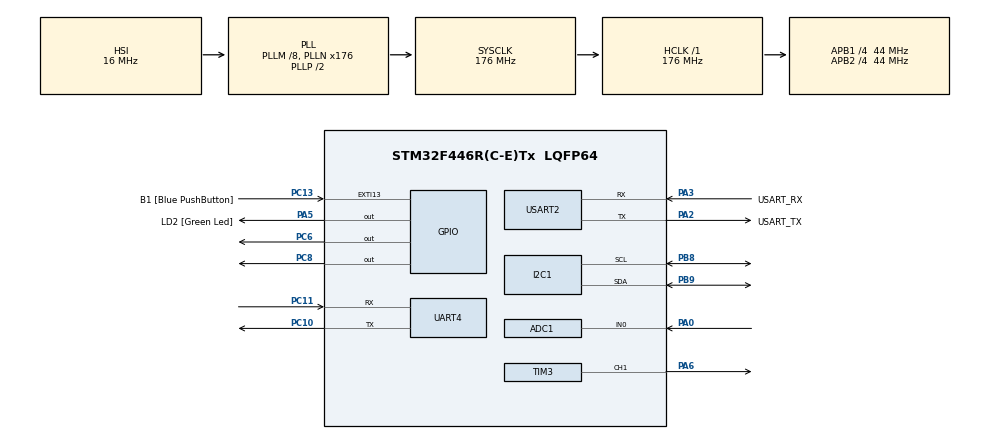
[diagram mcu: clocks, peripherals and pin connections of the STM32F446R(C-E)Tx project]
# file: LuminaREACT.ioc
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ADC1.Channel-0\#ChannelRegularConversion=ADC_CHANNEL_0
ADC1.ClockPrescaler=ADC_CLOCK_SYNC_PCLK_DIV4
ADC1.ContinuousConvMode=ENABLE
ADC1.DMAContinuousRequests=ENABLE
ADC1.EOCSelection=ADC_EOC_SEQ_CONV
ADC1.NbrOfConversion=1
ADC1.NbrOfConversionFlag=1
ADC1.Rank-0\#ChannelRegularConversion=1
ADC1.SamplingTime-0\#ChannelRegularConversion=ADC_SAMPLETIME_480CYCLES
ADC1.master=1
Dma.ADC1.0.Direction=DMA_PERIPH_TO_MEMORY
Dma.ADC1.0.FIFOMode=DMA_FIFOMODE_DISABLE
Dma.ADC1.0.Instance=DMA2_Stream0
Dma.ADC1.0.MemDataAlignment=DMA_MDATAALIGN_HALFWORD
Dma.ADC1.0.MemInc=DMA_MINC_ENABLE
Dma.ADC1.0.Mode=DMA_NORMAL
Dma.ADC1.0.PeriphDataAlignment=DMA_PDATAALIGN_HALFWORD
Dma.ADC1.0.PeriphInc=DMA_PINC_DISABLE
Dma.ADC1.0.Priority=DMA_PRIORITY_MEDIUM
Dma.Request0=ADC1
Dma.Request1=USART2_TX
Dma.Request2=USART2_RX
Dma.USART2_RX.2.Direction=DMA_PERIPH_TO_MEMORY
Dma.USART2_RX.2.FIFOMode=DMA_FIFOMODE_DISABLE
Dma.USART2_RX.2.Instance=DMA1_Stream5
Dma.USART2_RX.2.MemDataAlignment=DMA_MDATAALIGN_BYTE
Dma.USART2_RX.2.MemInc=DMA_MINC_ENABLE
Dma.USART2_RX.2.Mode=DMA_CIRCULAR
Dma.USART2_RX.2.PeriphDataAlignment=DMA_PDATAALIGN_BYTE
Dma.USART2_RX.2.PeriphInc=DMA_PINC_DISABLE
Dma.USART2_RX.2.Priority=DMA_PRIORITY_LOW
Dma.USART2_TX.1.Direction=DMA_MEMORY_TO_PERIPH
Dma.USART2_TX.1.FIFOMode=DMA_FIFOMODE_DISABLE
Dma.USART2_TX.1.Instance=DMA1_Stream6
Dma.USART2_TX.1.MemDataAlignment=DMA_MDATAALIGN_BYTE
Dma.USART2_TX.1.MemInc=DMA_MINC_ENABLE
Dma.USART2_TX.1.Mode=DMA_NORMAL
Dma.USART2_TX.1.PeriphDataAlignment=DMA_PDATAALIGN_BYTE
Dma.USART2_TX.1.PeriphInc=DMA_PINC_DISABLE
Dma.USART2_TX.1.Priority=DMA_PRIORITY_LOW
FREERTOS.BinarySemaphores01=xDriveLEDSemaphore,Dynamic,NULL,Available;xI2CuseSemaphore,Dynamic,NULL,Available;xAdcNewDataSemaphore,Dynamic,NULL,Depleted;xMaxAmplitudeSemaphore,Dynamic,NULL,Available;xFftBufferSemaphore,Dynamic,NULL,Available;xUART,Dynamic,NULL,Available
FREERTOS.Events01=fftNewData,Dynamic,NULL
FREERTOS.Queues01=xUartSendQueue,4,ussp_packet,0,Dynamic,NULL,NULL;xUartRxDMAQueue,10,void *,0,Dynamic,NULL,NULL
FREERTOS.Tasks01=xLedTask,24,128,ledTask,As weak,NULL,Dynamic,NULL,NULL;xFftTask,24,128,fftTask,As external,NULL,Dynamic,NULL,NULL;xCtrlTask,16,256,controlTask,As external,NULL,Dynamic,NULL,NULL;xTxTask,8,128,sendTask,As external,NULL,Dynamic,NULL,NULL
FREERTOS.Timers01=xAdcTimer,runADCCallback,osTimerPeriodic,As external,NULL,Dynamic,NULL
FREERTOS.configCHECK_FOR_STACK_OVERFLOW=2
FREERTOS.configENABLE_FPU=1
FREERTOS.configGENERATE_RUN_TIME_STATS=1
FREERTOS.configRECORD_STACK_HIGH_ADDRESS=1
FREERTOS.configUSE_STATS_FORMATTING_FUNCTIONS=1
Mcu.Family=STM32F4
Mcu.Name=STM32F446R(C-E)Tx
Mcu.Package=LQFP64
NVIC.DMA1_Stream5_IRQn=true\:9\:0\:true\:false\:false\:true\:false\:true\:true
NVIC.DMA1_Stream6_IRQn=true\:10\:0\:true\:false\:false\:true\:false\:true\:true
NVIC.DMA2_Stream0_IRQn=true\:5\:0\:false\:false\:true\:true\:false\:true\:true
NVIC.PriorityGroup=NVIC_PRIORITYGROUP_4
NVIC.TIM1_UP_TIM10_IRQn=true\:0\:0\:false\:false\:true\:false\:false\:true\:true
NVIC.TIM7_IRQn=true\:5\:0\:false\:false\:true\:true\:true\:true\:true
NVIC.TimeBase=TIM1_UP_TIM10_IRQn
NVIC.TimeBaseIP=TIM1
NVIC.USART2_IRQn=true\:5\:0\:false\:false\:false\:true\:true\:true\:true
PA0-WKUP.Signal=ADCx_IN0
PA13.GPIO_Label=TMS
PA13.Mode=Serial_Wire
PA13.Signal=SYS_JTMS-SWDIO
PA14.GPIO_Label=TCK
PA14.Mode=Serial_Wire
PA14.Signal=SYS_JTCK-SWCLK
PA2.GPIO_Label=USART_TX
PA2.Mode=Asynchronous
PA2.Signal=USART2_TX
PA3.GPIO_Label=USART_RX
PA3.Mode=Asynchronous
PA3.Signal=USART2_RX
PA5.GPIO_Label=LD2 [Green Led]
PA5.Signal=GPIO_Output
PA6.Signal=S_TIM3_CH1
PB3.GPIO_Label=SWO
PB3.Signal=SYS_JTDO-SWO
PB4.Signal=I2C3_SDA
PB8.GPIO_Pu=GPIO_PULLUP
PB8.Mode=I2C
PB8.Signal=I2C1_SCL
PB9.GPIO_Pu=GPIO_PULLUP
PB9.Mode=I2C
PB9.Signal=I2C1_SDA
PC10.Mode=Asynchronous
PC10.Signal=UART4_TX
PC11.Mode=Asynchronous
PC11.Signal=UART4_RX
PC13.GPIO_Label=B1 [Blue PushButton]
PC13.GPIO_ModeDefaultEXTI=GPIO_MODE_IT_FALLING
PC13.Signal=GPXTI13
PC14-OSC32_IN.Mode=LSE-External-Oscillator
PC14-OSC32_IN.Signal=RCC_OSC32_IN
PC15-OSC32_OUT.Mode=LSE-External-Oscillator
PC15-OSC32_OUT.Signal=RCC_OSC32_OUT
PC6.Signal=GPIO_Output
PC8.Signal=GPIO_Output
PH0-OSC_IN.Mode=HSE-External-Oscillator
PH0-OSC_IN.Signal=RCC_OSC_IN
PH1-OSC_OUT.Mode=HSE-External-Oscillator
PH1-OSC_OUT.Signal=RCC_OSC_OUT
ProjectManager.HeapSize=0x200
ProjectManager.StackSize=0x400
ProjectManager.TargetToolchain=STM32CubeIDE
RCC.48MHZClocksFreq_Value=84000000
RCC.AHBFreq_Value=176000000
RCC.APB1CLKDivider=RCC_HCLK_DIV4
RCC.APB1Freq_Value=44000000
RCC.APB1TimFreq_Value=88000000
RCC.APB2CLKDivider=RCC_HCLK_DIV4
RCC.APB2Freq_Value=44000000
RCC.APB2TimFreq_Value=88000000
RCC.CortexFreq_Value=176000000
RCC.FLatency-AdvancedSettings=FLASH_LATENCY_5
RCC.HCLKFreq_Value=176000000
RCC.HSE_VALUE=8000000
RCC.HSI_VALUE=16000000
RCC.PLLM=8
RCC.PLLN=176
RCC.PLLSAIP=RCC_PLLSAIP_DIV4
RCC.SYSCLKFreq_VALUE=176000000
RCC.SYSCLKSource=RCC_SYSCLKSOURCE_PLLCLK
RCC.USBCLockSelection=RCC_CLK48CLKSOURCE_PLLSAIP
RCC.USBFreq_Value=48000000
RCC.VCOOutputFreq_Value=352000000
SH.ADCx_IN0.0=ADC1_IN0,IN0
SH.S_TIM3_CH1.0=TIM3_CH1,PWM Generation1 CH1
TIM3.Channel-PWM\ Generation1\ CH1=TIM_CHANNEL_1
TIM7.Period=99
TIM7.Prescaler=87
UART4.VirtualMode=Asynchronous
USART2.VirtualMode=VM_ASYNC
VP_CRC_VS_CRC.Mode=CRC_Activate
VP_FREERTOS_VS_CMSIS_V2.Mode=CMSIS_V2
VP_SYS_VS_tim1.Mode=TIM1
VP_TIM7_VS_ClockSourceINT.Mode=Enable_Timer
board=NUCLEO-F446RE

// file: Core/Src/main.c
/* USER CODE BEGIN Header */
/**
  ******************************************************************************
  * @file           : main.c
  * @brief          : Main program body
  ******************************************************************************
  * @attention
  *
  * Copyright (c) 2024 STMicroelectronics.
  * All rights reserved.
  *
  * This software is licensed under terms that can be found in the LICENSE file
  * in the root directory of this software component.
  * If no LICENSE file comes with this software, it is provided AS-IS.
  *
  ******************************************************************************
  */
/* USER CODE END Header */
#include "main.h"
#include "cmsis_os.h"

/* USER CODE BEGIN Includes */

#include "luminareact.h"
#include "ussp.h"

/* USER CODE END Includes */

ADC_HandleTypeDef hadc1;
DMA_HandleTypeDef hdma_adc1;

CRC_HandleTypeDef hcrc;

I2C_HandleTypeDef hi2c1;

TIM_HandleTypeDef htim3;
TIM_HandleTypeDef htim7;

UART_HandleTypeDef huart4;

/* Definitions for xLedTask */
osThreadId_t xLedTaskHandle;
const osThreadAttr_t xLedTask_attributes = {
  .name = "xLedTask",
  .stack_size = 128 * 4,
  .priority = (osPriority_t) osPriorityNormal,
};
/* Definitions for xFftTask */
osThreadId_t xFftTaskHandle;
const osThreadAttr_t xFftTask_attributes = {
  .name = "xFftTask",
  .stack_size = 128 * 4,
  .priority = (osPriority_t) osPriorityNormal,
};
/* Definitions for xCtrlTask */
osThreadId_t xCtrlTaskHandle;
const osThreadAttr_t xCtrlTask_attributes = {
  .name = "xCtrlTask",
  .stack_size = 128 * 4,
  .priority = (osPriority_t) osPriorityBelowNormal,
};
/* Definitions for xTxTask */
osThreadId_t xTxTaskHandle;
const osThreadAttr_t xTxTask_attributes = {
  .name = "xTxTask",
  .stack_size = 128 * 4,
  .priority = (osPriority_t) osPriorityLow,
};
/* Definitions for xUartSendQueue */
osMessageQueueId_t xUartSendQueueHandle;
const osMessageQueueAttr_t xUartSendQueue_attributes = {
  .name = "xUartSendQueue"
};
/* Definitions for xUartRxDMAQueue */
osMessageQueueId_t xUartRxDMAQueueHandle;
const osMessageQueueAttr_t xUartRxDMAQueue_attributes = {
  .name = "xUartRxDMAQueue"
};
/* Definitions for xAdcTimer */
osTimerId_t xAdcTimerHandle;
const osTimerAttr_t xAdcTimer_attributes = {
  .name = "xAdcTimer"
};
/* Definitions for xDriveLEDSemaphore */
osSemaphoreId_t xDriveLEDSemaphoreHandle;
const osSemaphoreAttr_t xDriveLEDSemaphore_attributes = {
  .name = "xDriveLEDSemaphore"
};
/* Definitions for xI2CuseSemaphore */
osSemaphoreId_t xI2CuseSemaphoreHandle;
const osSemaphoreAttr_t xI2CuseSemaphore_attributes = {
  .name = "xI2CuseSemaphore"
};
/* Definitions for xAdcNewDataSemaphore */
osSemaphoreId_t xAdcNewDataSemaphoreHandle;
const osSemaphoreAttr_t xAdcNewDataSemaphore_attributes = {
  .name = "xAdcNewDataSemaphore"
};
/* Definitions for xMaxAmplitudeSemaphore */
osSemaphoreId_t xMaxAmplitudeSemaphoreHandle;
const osSemaphoreAttr_t xMaxAmplitudeSemaphore_attributes = {
  .name = "xMaxAmplitudeSemaphore"
};
/* Definitions for xFftBufferSemaphore */
osSemaphoreId_t xFftBufferSemaphoreHandle;
const osSemaphoreAttr_t xFftBufferSemaphore_attributes = {
  .name = "xFftBufferSemaphore"
};
/* Definitions for xUART */
osSemaphoreId_t xUARTHandle;
const osSemaphoreAttr_t xUART_attributes = {
  .name = "xUART"
};
/* Definitions for fftNewData */
osEventFlagsId_t fftNewDataHandle;
const osEventFlagsAttr_t fftNewData_attributes = {
  .name = "fftNewData"
};

void SystemClock_Config(void);
static void MX_GPIO_Init(void);
static void MX_DMA_Init(void);
static void MX_ADC1_Init(void);
static void MX_I2C1_Init(void);
static void MX_UART4_Init(void);
static void MX_TIM7_Init(void);
static void MX_CRC_Init(void);
static void MX_USART2_UART_Init(void);
static void MX_TIM3_Init(void);
void ledTask(void *argument);
extern void fftTask(void *argument);
extern void controlTask(void *argument);
extern void sendTask(void *argument);
extern void runADCCallback(void *argument);

int main(void)
{

  /* MCU Configuration--------------------------------------------------------*/

  /* Reset of all peripherals, Initializes the Flash interface and the Systick. */
  HAL_Init();

  /* Configure the system clock */
  SystemClock_Config();

  /* Initialize all configured peripherals */
  MX_GPIO_Init();
  MX_DMA_Init();
  MX_ADC1_Init();
  MX_I2C1_Init();
  MX_UART4_Init();
  MX_TIM7_Init();
  MX_CRC_Init();
  MX_USART2_UART_Init();
  MX_TIM3_Init();

  /* Init scheduler */
  osKernelInitialize();

  /* Create the semaphores(s) */
  /* creation of xDriveLEDSemaphore */
  xDriveLEDSemaphoreHandle = osSemaphoreNew(1, 1, &xDriveLEDSemaphore_attributes);

  /* creation of xI2CuseSemaphore */
  xI2CuseSemaphoreHandle = osSemaphoreNew(1, 1, &xI2CuseSemaphore_attributes);

  /* creation of xAdcNewDataSemaphore */
  xAdcNewDataSemaphoreHandle = osSemaphoreNew(1, 0, &xAdcNewDataSemaphore_attributes);

  /* creation of xMaxAmplitudeSemaphore */
  xMaxAmplitudeSemaphoreHandle = osSemaphoreNew(1, 1, &xMaxAmplitudeSemaphore_attributes);

  /* creation of xFftBufferSemaphore */
  xFftBufferSemaphoreHandle = osSemaphoreNew(1, 1, &xFftBufferSemaphore_attributes);

  /* creation of xUART */
  xUARTHandle = osSemaphoreNew(1, 1, &xUART_attributes);

  /* Create the timer(s) */
  /* creation of xAdcTimer */
  xAdcTimerHandle = osTimerNew(runADCCallback, osTimerPeriodic, NULL, &xAdcTimer_attributes);

  /* Create the queue(s) */
  /* creation of xUartSendQueue */
  xUartSendQueueHandle = osMessageQueueNew (4, sizeof(ussp_packet), &xUartSendQueue_attributes);

  /* creation of xUartRxDMAQueue */
  xUartRxDMAQueueHandle = osMessageQueueNew (10, sizeof(void *), &xUartRxDMAQueue_attributes);

  /* Create the thread(s) */
  /* creation of xLedTask */
  xLedTaskHandle = osThreadNew(ledTask, NULL, &xLedTask_attributes);

  /* creation of xFftTask */
  xFftTaskHandle = osThreadNew(fftTask, NULL, &xFftTask_attributes);

  /* creation of xCtrlTask */
  xCtrlTaskHandle = osThreadNew(controlTask, NULL, &xCtrlTask_attributes);

  /* creation of xTxTask */
  xTxTaskHandle = osThreadNew(sendTask, NULL, &xTxTask_attributes);

  /* Create the event(s) */
  /* creation of fftNewData */
  fftNewDataHandle = osEventFlagsNew(&fftNewData_attributes);

  /* Start scheduler */
  osKernelStart();

  /* We should never get here as control is now taken by the scheduler */

  /* Infinite loop */
  while (1)
  {

  }
}

void SystemClock_Config(void)
{
  RCC_OscInitTypeDef RCC_OscInitStruct = {0};
  RCC_ClkInitTypeDef RCC_ClkInitStruct = {0};

  /** Configure the main internal regulator output voltage
  */
  __HAL_RCC_PWR_CLK_ENABLE();
  __HAL_PWR_VOLTAGESCALING_CONFIG(PWR_REGULATOR_VOLTAGE_SCALE1);

  /** Initializes the RCC Oscillators according to the specified parameters
  * in the RCC_OscInitTypeDef structure.
  */
  RCC_OscInitStruct.OscillatorType = RCC_OSCILLATORTYPE_HSI;
  RCC_OscInitStruct.HSIState = RCC_HSI_ON;
  RCC_OscInitStruct.HSICalibrationValue = RCC_HSICALIBRATION_DEFAULT;
  RCC_OscInitStruct.PLL.PLLState = RCC_PLL_ON;
  RCC_OscInitStruct.PLL.PLLSource = RCC_PLLSOURCE_HSI;
  RCC_OscInitStruct.PLL.PLLM = 8;
  RCC_OscInitStruct.PLL.PLLN = 176;
  RCC_OscInitStruct.PLL.PLLP = RCC_PLLP_DIV2;
  RCC_OscInitStruct.PLL.PLLQ = 2;
  RCC_OscInitStruct.PLL.PLLR = 2;
  if (HAL_RCC_OscConfig(&RCC_OscInitStruct) != HAL_OK)
  {
    Error_Handler();
  }

  /** Activate the Over-Drive mode
  */
  if (HAL_PWREx_EnableOverDrive() != HAL_OK)
  {
    Error_Handler();
  }

  /** Initializes the CPU, AHB and APB buses clocks
  */
  RCC_ClkInitStruct.ClockType = RCC_CLOCKTYPE_HCLK|RCC_CLOCKTYPE_SYSCLK
                              |RCC_CLOCKTYPE_PCLK1|RCC_CLOCKTYPE_PCLK2;
  RCC_ClkInitStruct.SYSCLKSource = RCC_SYSCLKSOURCE_PLLCLK;
  RCC_ClkInitStruct.AHBCLKDivider = RCC_SYSCLK_DIV1;
  RCC_ClkInitStruct.APB1CLKDivider = RCC_HCLK_DIV4;
  RCC_ClkInitStruct.APB2CLKDivider = RCC_HCLK_DIV4;

  if (HAL_RCC_ClockConfig(&RCC_ClkInitStruct, FLASH_LATENCY_5) != HAL_OK)
  {
    Error_Handler();
  }
}

static void MX_ADC1_Init(void)
{

  ADC_ChannelConfTypeDef sConfig = {0};

  /** Configure the global features of the ADC (Clock, Resolution, Data Alignment and number of conversion)
  */
  hadc1.Instance = ADC1;
  hadc1.Init.ClockPrescaler = ADC_CLOCK_SYNC_PCLK_DIV4;
  hadc1.Init.Resolution = ADC_RESOLUTION_12B;
  hadc1.Init.ScanConvMode = DISABLE;
  hadc1.Init.ContinuousConvMode = ENABLE;
  hadc1.Init.DiscontinuousConvMode = DISABLE;
  hadc1.Init.ExternalTrigConvEdge = ADC_EXTERNALTRIGCONVEDGE_NONE;
  hadc1.Init.ExternalTrigConv = ADC_SOFTWARE_START;
  hadc1.Init.DataAlign = ADC_DATAALIGN_RIGHT;
  hadc1.Init.NbrOfConversion = 1;
  hadc1.Init.DMAContinuousRequests = ENABLE;
  hadc1.Init.EOCSelection = ADC_EOC_SINGLE_CONV;
  if (HAL_ADC_Init(&hadc1) != HAL_OK)
  {
    Error_Handler();
  }

  /** Configure for the selected ADC regular channel its corresponding rank in the sequencer and its sample time.
  */
  sConfig.Channel = ADC_CHANNEL_0;
  sConfig.Rank = 1;
  sConfig.SamplingTime = ADC_SAMPLETIME_480CYCLES;
  if (HAL_ADC_ConfigChannel(&hadc1, &sConfig) != HAL_OK)
  {
    Error_Handler();
  }

}

static void MX_CRC_Init(void)
{

  hcrc.Instance = CRC;
  if (HAL_CRC_Init(&hcrc) != HAL_OK)
  {
    Error_Handler();
  }

}

static void MX_I2C1_Init(void)
{

  hi2c1.Instance = I2C1;
  hi2c1.Init.ClockSpeed = 100000;
  hi2c1.Init.DutyCycle = I2C_DUTYCYCLE_2;
  hi2c1.Init.OwnAddress1 = 0;
  hi2c1.Init.AddressingMode = I2C_ADDRESSINGMODE_7BIT;
  hi2c1.Init.DualAddressMode = I2C_DUALADDRESS_DISABLE;
  hi2c1.Init.OwnAddress2 = 0;
  hi2c1.Init.GeneralCallMode = I2C_GENERALCALL_DISABLE;
  hi2c1.Init.NoStretchMode = I2C_NOSTRETCH_DISABLE;
  if (HAL_I2C_Init(&hi2c1) != HAL_OK)
  {
    Error_Handler();
  }

}

static void MX_TIM3_Init(void)
{

  TIM_MasterConfigTypeDef sMasterConfig = {0};
  TIM_OC_InitTypeDef sConfigOC = {0};

  htim3.Instance = TIM3;
  htim3.Init.Prescaler = 0;
  htim3.Init.CounterMode = TIM_COUNTERMODE_UP;
  htim3.Init.Period = 65535;
  htim3.Init.ClockDivision = TIM_CLOCKDIVISION_DIV1;
  htim3.Init.AutoReloadPreload = TIM_AUTORELOAD_PRELOAD_DISABLE;
  if (HAL_TIM_PWM_Init(&htim3) != HAL_OK)
  {
    Error_Handler();
  }
  sMasterConfig.MasterOutputTrigger = TIM_TRGO_RESET;
  sMasterConfig.MasterSlaveMode = TIM_MASTERSLAVEMODE_DISABLE;
  if (HAL_TIMEx_MasterConfigSynchronization(&htim3, &sMasterConfig) != HAL_OK)
  {
    Error_Handler();
  }
  sConfigOC.OCMode = TIM_OCMODE_PWM1;
  sConfigOC.Pulse = 0;
  sConfigOC.OCPolarity = TIM_OCPOLARITY_HIGH;
  sConfigOC.OCFastMode = TIM_OCFAST_DISABLE;
  if (HAL_TIM_PWM_ConfigChannel(&htim3, &sConfigOC, TIM_CHANNEL_1) != HAL_OK)
  {
    Error_Handler();
  }
  HAL_TIM_MspPostInit(&htim3);

}

static void MX_TIM7_Init(void)
{

  TIM_MasterConfigTypeDef sMasterConfig = {0};

  htim7.Instance = TIM7;
  htim7.Init.Prescaler = 87;
  htim7.Init.CounterMode = TIM_COUNTERMODE_UP;
  htim7.Init.Period = 99;
  htim7.Init.AutoReloadPreload = TIM_AUTORELOAD_PRELOAD_DISABLE;
  if (HAL_TIM_Base_Init(&htim7) != HAL_OK)
  {
    Error_Handler();
  }
  sMasterConfig.MasterOutputTrigger = TIM_TRGO_RESET;
  sMasterConfig.MasterSlaveMode = TIM_MASTERSLAVEMODE_DISABLE;
  if (HAL_TIMEx_MasterConfigSynchronization(&htim7, &sMasterConfig) != HAL_OK)
  {
    Error_Handler();
  }

}

static void MX_UART4_Init(void)
{

  huart4.Instance = UART4;
  huart4.Init.BaudRate = 115200;
  huart4.Init.WordLength = UART_WORDLENGTH_8B;
  huart4.Init.StopBits = UART_STOPBITS_1;
  huart4.Init.Parity = UART_PARITY_NONE;
  huart4.Init.Mode = UART_MODE_TX_RX;
  huart4.Init.HwFlowCtl = UART_HWCONTROL_NONE;
  huart4.Init.OverSampling = UART_OVERSAMPLING_16;
  if (HAL_UART_Init(&huart4) != HAL_OK)
  {
    Error_Handler();
  }

}

static void MX_USART2_UART_Init(void)
{

  LL_USART_InitTypeDef USART_InitStruct = {0};

  LL_GPIO_InitTypeDef GPIO_InitStruct = {0};

  /* Peripheral clock enable */
  LL_APB1_GRP1_EnableClock(LL_APB1_GRP1_PERIPH_USART2);

  LL_AHB1_GRP1_EnableClock(LL_AHB1_GRP1_PERIPH_GPIOA);
  /**USART2 GPIO Configuration
  PA2   ------> USART2_TX
  PA3   ------> USART2_RX
  */
  GPIO_InitStruct.Pin = LL_GPIO_PIN_2|LL_GPIO_PIN_3;
  GPIO_InitStruct.Mode = LL_GPIO_MODE_ALTERNATE;
  GPIO_InitStruct.Speed = LL_GPIO_SPEED_FREQ_VERY_HIGH;
  GPIO_InitStruct.OutputType = LL_GPIO_OUTPUT_PUSHPULL;
  GPIO_InitStruct.Pull = LL_GPIO_PULL_NO;
  GPIO_InitStruct.Alternate = LL_GPIO_AF_7;
  LL_GPIO_Init(GPIOA, &GPIO_InitStruct);

  /* USART2 DMA Init */

  /* USART2_TX Init */
  LL_DMA_SetChannelSelection(DMA1, LL_DMA_STREAM_6, LL_DMA_CHANNEL_4);

  LL_DMA_SetDataTransferDirection(DMA1, LL_DMA_STREAM_6, LL_DMA_DIRECTION_MEMORY_TO_PERIPH);

  LL_DMA_SetStreamPriorityLevel(DMA1, LL_DMA_STREAM_6, LL_DMA_PRIORITY_LOW);

  LL_DMA_SetMode(DMA1, LL_DMA_STREAM_6, LL_DMA_MODE_NORMAL);

  LL_DMA_SetPeriphIncMode(DMA1, LL_DMA_STREAM_6, LL_DMA_PERIPH_NOINCREMENT);

  LL_DMA_SetMemoryIncMode(DMA1, LL_DMA_STREAM_6, LL_DMA_MEMORY_INCREMENT);

  LL_DMA_SetPeriphSize(DMA1, LL_DMA_STREAM_6, LL_DMA_PDATAALIGN_BYTE);

  LL_DMA_SetMemorySize(DMA1, LL_DMA_STREAM_6, LL_DMA_MDATAALIGN_BYTE);

  LL_DMA_DisableFifoMode(DMA1, LL_DMA_STREAM_6);

  /* USART2_RX Init */
  LL_DMA_SetChannelSelection(DMA1, LL_DMA_STREAM_5, LL_DMA_CHANNEL_4);

  LL_DMA_SetDataTransferDirection(DMA1, LL_DMA_STREAM_5, LL_DMA_DIRECTION_PERIPH_TO_MEMORY);

  LL_DMA_SetStreamPriorityLevel(DMA1, LL_DMA_STREAM_5, LL_DMA_PRIORITY_LOW);

  LL_DMA_SetMode(DMA1, LL_DMA_STREAM_5, LL_DMA_MODE_CIRCULAR);

  LL_DMA_SetPeriphIncMode(DMA1, LL_DMA_STREAM_5, LL_DMA_PERIPH_NOINCREMENT);

  LL_DMA_SetMemoryIncMode(DMA1, LL_DMA_STREAM_5, LL_DMA_MEMORY_INCREMENT);

  LL_DMA_SetPeriphSize(DMA1, LL_DMA_STREAM_5, LL_DMA_PDATAALIGN_BYTE);

  LL_DMA_SetMemorySize(DMA1, LL_DMA_STREAM_5, LL_DMA_MDATAALIGN_BYTE);

  LL_DMA_DisableFifoMode(DMA1, LL_DMA_STREAM_5);

  /* USART2 interrupt Init */
  NVIC_SetPriority(USART2_IRQn, NVIC_EncodePriority(NVIC_GetPriorityGrouping(),5, 0));
  NVIC_EnableIRQ(USART2_IRQn);

  /* USER CODE BEGIN USART2_Init 1 */

  LL_DMA_SetPeriphAddress(DMA1, LL_DMA_STREAM_6, LL_USART_DMA_GetRegAddr(USART2));
  LL_DMA_EnableIT_TC(DMA1, LL_DMA_STREAM_6);

  /* USER CODE END USART2_Init 1 */
  USART_InitStruct.BaudRate = 115200;
  USART_InitStruct.DataWidth = LL_USART_DATAWIDTH_8B;
  USART_InitStruct.StopBits = LL_USART_STOPBITS_1;
  USART_InitStruct.Parity = LL_USART_PARITY_NONE;
  USART_InitStruct.TransferDirection = LL_USART_DIRECTION_TX_RX;
  USART_InitStruct.HardwareFlowControl = LL_USART_HWCONTROL_NONE;
  USART_InitStruct.OverSampling = LL_USART_OVERSAMPLING_16;
  LL_USART_Init(USART2, &USART_InitStruct);
  LL_USART_ConfigAsyncMode(USART2);
  LL_USART_Enable(USART2);
  /* USER CODE BEGIN USART2_Init 2 */

  LL_USART_EnableDMAReq_TX(USART2);

  /* USER CODE END USART2_Init 2 */

}

static void MX_DMA_Init(void)
{

  /* Init with LL driver */
  /* DMA controller clock enable */
  LL_AHB1_GRP1_EnableClock(LL_AHB1_GRP1_PERIPH_DMA2);
  LL_AHB1_GRP1_EnableClock(LL_AHB1_GRP1_PERIPH_DMA1);

  /* DMA interrupt init */
  /* DMA1_Stream5_IRQn interrupt configuration */
  NVIC_SetPriority(DMA1_Stream5_IRQn, NVIC_EncodePriority(NVIC_GetPriorityGrouping(),9, 0));
  NVIC_EnableIRQ(DMA1_Stream5_IRQn);
  /* DMA1_Stream6_IRQn interrupt configuration */
  NVIC_SetPriority(DMA1_Stream6_IRQn, NVIC_EncodePriority(NVIC_GetPriorityGrouping(),10, 0));
  NVIC_EnableIRQ(DMA1_Stream6_IRQn);
  /* DMA2_Stream0_IRQn interrupt configuration */
  HAL_NVIC_SetPriority(DMA2_Stream0_IRQn, 5, 0);
  HAL_NVIC_EnableIRQ(DMA2_Stream0_IRQn);

}

static void MX_GPIO_Init(void)
{
  GPIO_InitTypeDef GPIO_InitStruct = {0};

  /* GPIO Ports Clock Enable */
  __HAL_RCC_GPIOC_CLK_ENABLE();
  __HAL_RCC_GPIOH_CLK_ENABLE();
  __HAL_RCC_GPIOA_CLK_ENABLE();
  __HAL_RCC_GPIOB_CLK_ENABLE();

  /*Configure GPIO pin Output Level */
  HAL_GPIO_WritePin(LD2_GPIO_Port, LD2_Pin, GPIO_PIN_RESET);

  /*Configure GPIO pin Output Level */
  HAL_GPIO_WritePin(GPIOC, GPIO_PIN_6|GPIO_PIN_8, GPIO_PIN_RESET);

  /*Configure GPIO pin : B1_Pin */
  GPIO_InitStruct.Pin = B1_Pin;
  GPIO_InitStruct.Mode = GPIO_MODE_IT_FALLING;
  GPIO_InitStruct.Pull = GPIO_NOPULL;
  HAL_GPIO_Init(B1_GPIO_Port, &GPIO_InitStruct);

  /*Configure GPIO pin : LD2_Pin */
  GPIO_InitStruct.Pin = LD2_Pin;
  GPIO_InitStruct.Mode = GPIO_MODE_OUTPUT_PP;
  GPIO_InitStruct.Pull = GPIO_NOPULL;
  GPIO_InitStruct.Speed = GPIO_SPEED_FREQ_LOW;
  HAL_GPIO_Init(LD2_GPIO_Port, &GPIO_InitStruct);

  /*Configure GPIO pins : PC6 PC8 */
  GPIO_InitStruct.Pin = GPIO_PIN_6|GPIO_PIN_8;
  GPIO_InitStruct.Mode = GPIO_MODE_OUTPUT_PP;
  GPIO_InitStruct.Pull = GPIO_NOPULL;
  GPIO_InitStruct.Speed = GPIO_SPEED_FREQ_LOW;
  HAL_GPIO_Init(GPIOC, &GPIO_InitStruct);

  /*Configure GPIO pin : PB4 */
  GPIO_InitStruct.Pin = GPIO_PIN_4;
  GPIO_InitStruct.Mode = GPIO_MODE_AF_OD;
  GPIO_InitStruct.Pull = GPIO_NOPULL;
  GPIO_InitStruct.Speed = GPIO_SPEED_FREQ_VERY_HIGH;
  GPIO_InitStruct.Alternate = GPIO_AF4_I2C3;
  HAL_GPIO_Init(GPIOB, &GPIO_InitStruct);

}

__weak void ledTask(void *argument)
{
  for(;;)
  {
    osDelay(1);
  }
}

void HAL_TIM_PeriodElapsedCallback(TIM_HandleTypeDef *htim)
{
  if (htim->Instance == TIM1) {
    HAL_IncTick();
  }
}

void Error_Handler(void)
{
  __disable_irq();
  while (1)
  {
  }
}

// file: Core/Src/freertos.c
/* USER CODE BEGIN Header */
/**
  ******************************************************************************
  * File Name          : freertos.c
  * Description        : Code for freertos applications
  ******************************************************************************
  * @attention
  *
  * Copyright (c) 2024 STMicroelectronics.
  * All rights reserved.
  *
  * This software is licensed under terms that can be found in the LICENSE file
  * in the root directory of this software component.
  * If no LICENSE file comes with this software, it is provided AS-IS.
  *
  ******************************************************************************
  */
/* USER CODE END Header */

#include "FreeRTOS.h"
#include "task.h"
#include "main.h"

/* USER CODE BEGIN Variables */
volatile uint32_t ulStatsTimerTicks;
extern TIM_HandleTypeDef htim7;

/* USER CODE END Variables */

/* Hook prototypes */
void configureTimerForRunTimeStats(void);
unsigned long getRunTimeCounterValue(void);
void vApplicationStackOverflowHook(xTaskHandle xTask, signed char *pcTaskName);

/* USER CODE BEGIN 1 */
/* Functions needed when configGENERATE_RUN_TIME_STATS is on */
__weak void configureTimerForRunTimeStats(void)
{
	ulStatsTimerTicks=0;
	HAL_TIM_Base_Start_IT(&htim7);
}

__weak unsigned long getRunTimeCounterValue(void)
{
	return ulStatsTimerTicks;
}
/* USER CODE END 1 */

/* USER CODE BEGIN 4 */
void vApplicationStackOverflowHook(xTaskHandle xTask, signed char *pcTaskName)
{
   /* Run time stack overflow checking is performed if
   configCHECK_FOR_STACK_OVERFLOW is defined to 1 or 2. This hook function is
   called if a stack overflow is detected. */
	while(1) {

	}
}
/* USER CODE END 4 */
